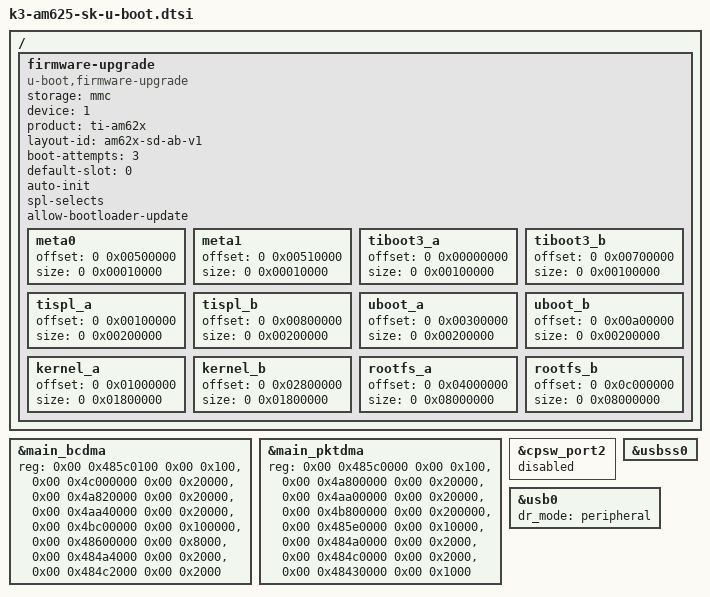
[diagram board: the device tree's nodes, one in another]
// SPDX-License-Identifier: GPL-2.0
/*
 * Common AM625 SK dts file for SPLs
 * Copyright (C) 2021-2022 Texas Instruments Incorporated - https://www.ti.com/
 */

#include "k3-am625-sk-binman.dtsi"

/ {
	firmware-upgrade {
		compatible = "u-boot,firmware-upgrade";
		storage = "mmc";
		device = <1>;
		product = "ti-am62x";
		layout-id = "am62x-sd-ab-v1";
		boot-attempts = <3>;
		default-slot = <0>;
		auto-init;
		spl-selects;
		allow-bootloader-update;

		meta0 { offset = <0 0x00500000>; size = <0 0x00010000>; };
		meta1 { offset = <0 0x00510000>; size = <0 0x00010000>; };

		/* Redundant U-Boot environments: 0x600000 and 0x620000. */
		tiboot3_a { offset = <0 0x00000000>; size = <0 0x00100000>; };
		tiboot3_b { offset = <0 0x00700000>; size = <0 0x00100000>; };
		tispl_a { offset = <0 0x00100000>; size = <0 0x00200000>; };
		tispl_b { offset = <0 0x00800000>; size = <0 0x00200000>; };
		uboot_a { offset = <0 0x00300000>; size = <0 0x00200000>; };
		uboot_b { offset = <0 0x00a00000>; size = <0 0x00200000>; };
		kernel_a { offset = <0 0x01000000>; size = <0 0x01800000>; };
		kernel_b { offset = <0 0x02800000>; size = <0 0x01800000>; };
		rootfs_a { offset = <0 0x04000000>; size = <0 0x08000000>; };
		rootfs_b { offset = <0 0x0c000000>; size = <0 0x08000000>; };
	};
};

&main_bcdma {
	reg = <0x00 0x485c0100 0x00 0x100>,
	      <0x00 0x4c000000 0x00 0x20000>,
	      <0x00 0x4a820000 0x00 0x20000>,
	      <0x00 0x4aa40000 0x00 0x20000>,
	      <0x00 0x4bc00000 0x00 0x100000>,
	      <0x00 0x48600000 0x00 0x8000>,
	      <0x00 0x484a4000 0x00 0x2000>,
	      <0x00 0x484c2000 0x00 0x2000>;
	reg-names = "gcfg", "bchanrt", "rchanrt", "tchanrt",
		    "ringrt" , "cfg", "tchan", "rchan";
};

&main_pktdma {
	reg = <0x00 0x485c0000 0x00 0x100>,
	      <0x00 0x4a800000 0x00 0x20000>,
	      <0x00 0x4aa00000 0x00 0x20000>,
	      <0x00 0x4b800000 0x00 0x200000>,
	      <0x00 0x485e0000 0x00 0x10000>,
	      <0x00 0x484a0000 0x00 0x2000>,
	      <0x00 0x484c0000 0x00 0x2000>,
	      <0x00 0x48430000 0x00 0x1000>;
	reg-names = "gcfg", "rchanrt", "tchanrt", "ringrt",
		    "cfg", "tchan", "rchan", "rflow";
	bootph-all;
};

&cpsw_port2 {
	status = "disabled";
};

&usbss0 {
	bootph-all;
};

&usb0 {
	dr_mode = "peripheral";
	bootph-all;
};
